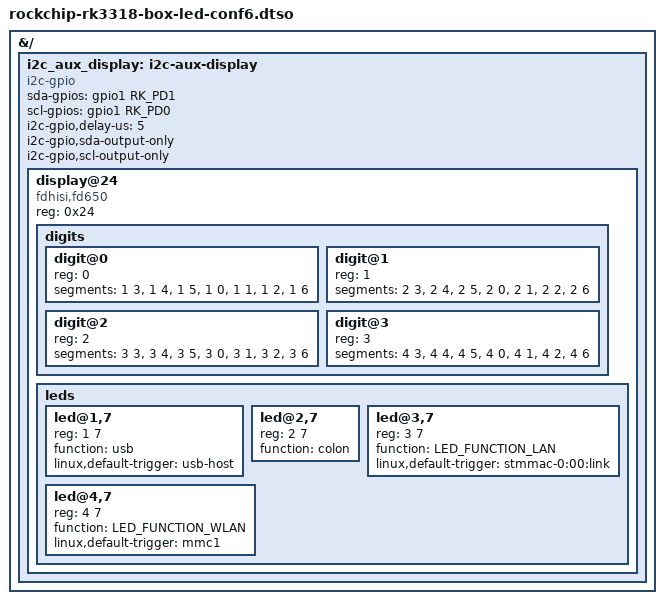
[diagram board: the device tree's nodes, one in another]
/dts-v1/;
/plugin/;

#include <dt-bindings/gpio/gpio.h>
#include <dt-bindings/leds/common.h>
#include <dt-bindings/pinctrl/rockchip.h>

/**
 * T98_RK3318 (Hongtop H50)
 */

&{/} {

	i2c_aux_display: i2c-aux-display {

		compatible = "i2c-gpio";
		sda-gpios = <&gpio1 RK_PD1 (GPIO_ACTIVE_HIGH|GPIO_OPEN_DRAIN)>;
		scl-gpios = <&gpio1 RK_PD0 (GPIO_ACTIVE_HIGH|GPIO_OPEN_DRAIN)>;
		i2c-gpio,delay-us = <5>;
		i2c-gpio,sda-output-only;
		i2c-gpio,scl-output-only;
		#address-cells = <1>;
		#size-cells = <0>;

		display@24 {
			compatible = "fdhisi,fd650";
			reg = <0x24>;

			digits {
				#address-cells = <1>;
				#size-cells = <0>;

				digit@0 {
					reg = <0>;
					segments = <1 3>, <1 4>, <1 5>, <1 0>, <1 1>, <1 2>, <1 6>;
				};

				digit@1 {
					reg = <1>;
					segments = <2 3>, <2 4>, <2 5>, <2 0>, <2 1>, <2 2>, <2 6>;
				};

				digit@2 {
					reg = <2>;
					segments = <3 3>, <3 4>, <3 5>, <3 0>, <3 1>, <3 2>, <3 6>;
				};

				digit@3{
					reg = <3>;
					segments = <4 3>, <4 4>, <4 5>, <4 0>, <4 1>, <4 2>, <4 6>;
				};

			};

			leds {
				#address-cells = <2>;
				#size-cells = <0>;

				led@1,7 {
					reg = <1 7>;
					function = "usb";
					linux,default-trigger = "usb-host";
				};

				led@2,7 {
					reg = <2 7>;
					function = "colon";
				};

				led@3,7 {
					reg = <3 7>;
					function = LED_FUNCTION_LAN;
					linux,default-trigger = "stmmac-0:00:link";
				};

				led@4,7 {
					reg = <4 7>;
					function = LED_FUNCTION_WLAN;
					linux,default-trigger = "mmc1";
				};

			};

		};

	};

};
